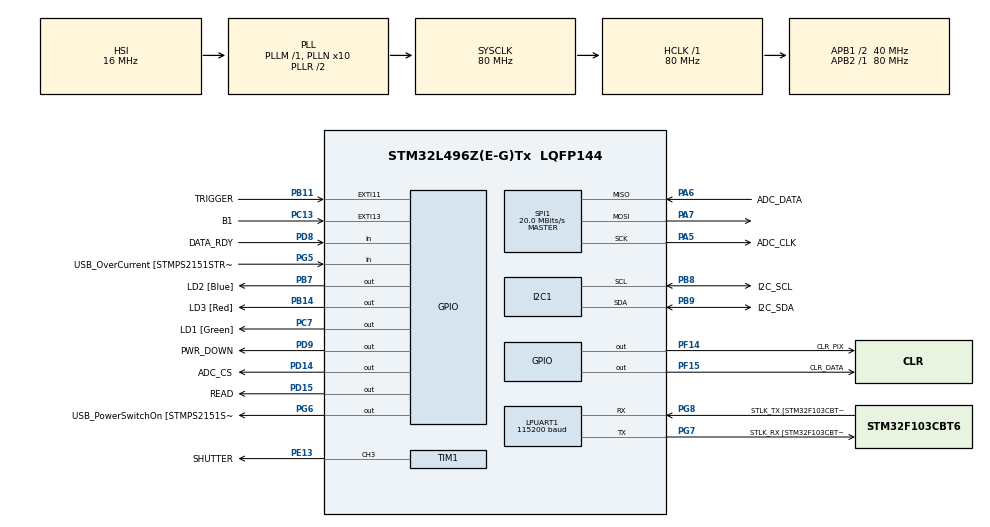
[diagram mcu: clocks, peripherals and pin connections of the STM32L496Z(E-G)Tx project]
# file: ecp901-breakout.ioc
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Dma.LPUART_RX.0.Direction=DMA_PERIPH_TO_MEMORY
Dma.LPUART_RX.0.Instance=DMA2_Channel7
Dma.LPUART_RX.0.MemDataAlignment=DMA_MDATAALIGN_BYTE
Dma.LPUART_RX.0.MemInc=DMA_MINC_ENABLE
Dma.LPUART_RX.0.Mode=DMA_CIRCULAR
Dma.LPUART_RX.0.PeriphDataAlignment=DMA_PDATAALIGN_BYTE
Dma.LPUART_RX.0.PeriphInc=DMA_PINC_DISABLE
Dma.LPUART_RX.0.Priority=DMA_PRIORITY_LOW
Dma.Request0=LPUART_RX
I2C1.Timing=0x00909BEB
LPUART1.BaudRate=115200
LPUART1.WordLength=UART_WORDLENGTH_8B
Mcu.Family=STM32L4
Mcu.Name=STM32L496Z(E-G)Tx
Mcu.Package=LQFP144
NVIC.DMA2_Channel7_IRQn=true\:0\:0\:false\:false\:true\:false\:true
NVIC.EXTI15_10_IRQn=true\:0\:0\:false\:false\:true\:true\:true
NVIC.PriorityGroup=NVIC_PRIORITYGROUP_4
PA10.GPIO_Label=USB_ID
PA10.Signal=USB_OTG_FS_ID
PA11.GPIO_Label=USB_DM
PA11.Signal=USB_OTG_FS_DM
PA12.GPIO_Label=USB_DP
PA12.Signal=USB_OTG_FS_DP
PA13\ (JTMS/SWDIO).GPIO_Label=TMS
PA13\ (JTMS/SWDIO).Mode=Trace_Asynchronous_SW
PA13\ (JTMS/SWDIO).Signal=SYS_JTMS-SWDIO
PA14\ (JTCK/SWCLK).GPIO_Label=TCK
PA14\ (JTCK/SWCLK).Mode=Trace_Asynchronous_SW
PA14\ (JTCK/SWCLK).Signal=SYS_JTCK-SWCLK
PA5.GPIO_Label=ADC_CLK
PA5.GPIO_PuPd=GPIO_NOPULL
PA5.GPIO_Speed=GPIO_SPEED_FREQ_MEDIUM
PA5.Mode=Full_Duplex_Master
PA5.Signal=SPI1_SCK
PA6.GPIO_Label=ADC_DATA
PA6.GPIO_PuPd=GPIO_NOPULL
PA6.GPIO_Speed=GPIO_SPEED_FREQ_LOW
PA6.Mode=Full_Duplex_Master
PA6.Signal=SPI1_MISO
PA7.GPIO_Speed=GPIO_SPEED_FREQ_LOW
PA7.Mode=Full_Duplex_Master
PA7.Signal=SPI1_MOSI
PA8.GPIO_Label=USB_SOF [TP1]
PA8.Signal=USB_OTG_FS_SOF
PA9.GPIO_Label=USB_VBUS
PA9.Signal=USB_OTG_FS_VBUS
PB11.GPIO_Label=TRIGGER
PB11.GPIO_ModeDefaultEXTI=GPIO_MODE_IT_RISING_FALLING
PB11.GPIO_PuPd=GPIO_PULLDOWN
PB11.Signal=GPXTI11
PB14.GPIO_Label=LD3 [Red]
PB14.Signal=GPIO_Output
PB3\ (JTDO/TRACESWO).GPIO_Label=SWO
PB3\ (JTDO/TRACESWO).Mode=Trace_Asynchronous_SW
PB3\ (JTDO/TRACESWO).Signal=SYS_JTDO-SWO
PB7.GPIO_Label=LD2 [Blue]
PB7.Signal=GPIO_Output
PB8.GPIO_Label=I2C_SCL
PB8.GPIO_Speed=GPIO_SPEED_FREQ_LOW
PB8.Mode=I2C
PB8.Signal=I2C1_SCL
PB9.GPIO_Label=I2C_SDA
PB9.GPIO_Speed=GPIO_SPEED_FREQ_LOW
PB9.Mode=I2C
PB9.Signal=I2C1_SDA
PC13.GPIO_Label=B1
PC13.Signal=GPXTI13
PC14-OSC32_IN\ (PC14).Mode=LSE-External-Oscillator
PC14-OSC32_IN\ (PC14).Signal=RCC_OSC32_IN
PC15-OSC32_OUT\ (PC15).Mode=LSE-External-Oscillator
PC15-OSC32_OUT\ (PC15).Signal=RCC_OSC32_OUT
PC7.GPIO_Label=LD1 [Green]
PC7.Signal=GPIO_Output
PD14.GPIO_Label=ADC_CS
PD14.Signal=GPIO_Output
PD15.GPIO_Label=READ
PD15.Signal=GPIO_Output
PD8.GPIO_Label=DATA_RDY
PD8.Signal=GPIO_Input
PD9.GPIO_Label=PWR_DOWN
PD9.GPIO_PuPd=GPIO_PULLUP
PD9.Signal=GPIO_Output
PE13.GPIO_Label=SHUTTER
PE13.Signal=S_TIM1_CH3
PF14.GPIO_Label=CLR_PIX
PF14.Signal=GPIO_Output
PF15.GPIO_Label=CLR_DATA
PF15.Signal=GPIO_Output
PG5.GPIO_Label=USB_OverCurrent [STMPS2151STR_FAULT]
PG5.Signal=GPIO_Input
PG6.GPIO_Label=USB_PowerSwitchOn [STMPS2151STR_EN]
PG6.Signal=GPIO_Output
PG7.GPIO_Label=STLK_RX [STM32F103CBT6_PA3]
PG7.Mode=Asynchronous
PG7.Signal=LPUART1_TX
PG8.GPIO_Label=STLK_TX [STM32F103CBT6_PA2]
PG8.Mode=Asynchronous
PG8.Signal=LPUART1_RX
PH1-OSC_OUT\ (PH1).Signal=RCC_OSC_OUT
ProjectManager.HeapSize=0x200
ProjectManager.StackSize=0x400
ProjectManager.TargetToolchain=STM32CubeIDE
RCC.48MHZClocksFreq_Value=24000000
RCC.ADCFreq_Value=192000000
RCC.AHBFreq_Value=80000000
RCC.APB1CLKDivider=RCC_HCLK_DIV2
RCC.APB1Freq_Value=40000000
RCC.APB1TimFreq_Value=80000000
RCC.APB2Freq_Value=80000000
RCC.APB2TimFreq_Value=80000000
RCC.CortexFreq_Value=80000000
RCC.HCLKFreq_Value=80000000
RCC.HSE_VALUE=8000000
RCC.HSI48_VALUE=48000000
RCC.HSI_VALUE=16000000
RCC.MSI_VALUE=4000000
RCC.PLLMUL=RCC_PLL_MUL9
RCC.PLLN=10
RCC.PLLSAI1N=24
RCC.PLLSourceVirtual=RCC_PLLSOURCE_HSI
RCC.PRESCALERUSB=RCC_USBCLKSOURCE_PLL_DIV1_5
RCC.SYSCLKFreq_VALUE=80000000
RCC.SYSCLKSource=RCC_SYSCLKSOURCE_PLLCLK
RCC.SYSCLKSourceVirtual=RCC_SYSCLKSOURCE_PLLCLK
RCC.USBFreq_Value=192000000
RCC.VCOOutputFreq_Value=160000000
SH.S_TIM1_CH3.0=TIM1_CH3,PWM Generation3 CH3
SPI1.BaudRatePrescaler=SPI_BAUDRATEPRESCALER_4
SPI1.CLKPhase=SPI_PHASE_2EDGE
SPI1.CLKPolarity=SPI_POLARITY_HIGH
SPI1.CalculateBaudRate=20.0 MBits/s
SPI1.DataSize=SPI_DATASIZE_8BIT
SPI1.Direction=SPI_DIRECTION_2LINES
SPI1.FirstBit=SPI_FIRSTBIT_MSB
SPI1.Mode=SPI_MODE_MASTER
SPI1.VirtualType=VM_MASTER
TIM1.Channel-PWM\ Generation3\ CH3=TIM_CHANNEL_3
TIM1.ClockDivision=TIM_CLOCKDIVISION_DIV1
TIM1.OCMode_PWM-PWM\ Generation3\ CH3=TIM_OCMODE_PWM2
VP_TIM1_VS_ClockSourceINT.Mode=Internal
VP_TIM1_VS_OPM.Mode=OPM_bit
board=NUCLEO-L496ZG

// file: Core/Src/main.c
/* USER CODE BEGIN Header */
/**
  ******************************************************************************
  * @file           : main.c
  * @brief          : Main program body
  ******************************************************************************
  * @attention
  *
  * <h2><center>&copy; Copyright (c) 2020 STMicroelectronics.
  * All rights reserved.</center></h2>
  *
  * This software component is licensed by ST under BSD 3-Clause license,
  * the "License"; You may not use this file except in compliance with the
  * License. You may obtain a copy of the License at:
  *                        opensource.org/licenses/BSD-3-Clause
  *
  ******************************************************************************
  */
/* USER CODE END Header */
#include "main.h"

/* USER CODE BEGIN Includes */
#include "App.hpp"
#include "dwt_stm32_delay.h"
/* USER CODE END Includes */

I2C_HandleTypeDef hi2c1;

UART_HandleTypeDef hlpuart1;
DMA_HandleTypeDef hdma_lpuart_rx;

SPI_HandleTypeDef hspi1;

TIM_HandleTypeDef htim1;

void SystemClock_Config(void);
static void MX_GPIO_Init(void);
static void MX_DMA_Init(void);
static void MX_LPUART1_UART_Init(void);
static void MX_I2C1_Init(void);
static void MX_SPI1_Init(void);
static void MX_TIM1_Init(void);

int main(void)
{

  /* MCU Configuration--------------------------------------------------------*/

  /* Reset of all peripherals, Initializes the Flash interface and the Systick. */
  HAL_Init();

  /* Configure the system clock */
  SystemClock_Config();

  /* Initialize all configured peripherals */
  MX_GPIO_Init();
  MX_DMA_Init();
  MX_LPUART1_UART_Init();
  MX_I2C1_Init();
  MX_SPI1_Init();
  MX_TIM1_Init();
  /* USER CODE BEGIN 2 */
  // init us delay function
  if (DWT_Delay_Init()) {
	  // failed to init delay
  }
  App_Setup(&hi2c1, &hlpuart1, &hspi1, &htim1);
  /* USER CODE END 2 */

  /* Infinite loop */
  /* USER CODE BEGIN WHILE */
  while (1)
  {
	  App_Loop();
    /* USER CODE END WHILE */

  }
}

void SystemClock_Config(void)
{
  RCC_OscInitTypeDef RCC_OscInitStruct = {0};
  RCC_ClkInitTypeDef RCC_ClkInitStruct = {0};
  RCC_PeriphCLKInitTypeDef PeriphClkInit = {0};

  /** Initializes the RCC Oscillators according to the specified parameters
  * in the RCC_OscInitTypeDef structure.
  */
  RCC_OscInitStruct.OscillatorType = RCC_OSCILLATORTYPE_HSI;
  RCC_OscInitStruct.HSIState = RCC_HSI_ON;
  RCC_OscInitStruct.HSICalibrationValue = RCC_HSICALIBRATION_DEFAULT;
  RCC_OscInitStruct.PLL.PLLState = RCC_PLL_ON;
  RCC_OscInitStruct.PLL.PLLSource = RCC_PLLSOURCE_HSI;
  RCC_OscInitStruct.PLL.PLLM = 1;
  RCC_OscInitStruct.PLL.PLLN = 10;
  RCC_OscInitStruct.PLL.PLLP = RCC_PLLP_DIV2;
  RCC_OscInitStruct.PLL.PLLQ = RCC_PLLQ_DIV2;
  RCC_OscInitStruct.PLL.PLLR = RCC_PLLR_DIV2;
  if (HAL_RCC_OscConfig(&RCC_OscInitStruct) != HAL_OK)
  {
    Error_Handler();
  }
  /** Initializes the CPU, AHB and APB buses clocks
  */
  RCC_ClkInitStruct.ClockType = RCC_CLOCKTYPE_HCLK|RCC_CLOCKTYPE_SYSCLK
                              |RCC_CLOCKTYPE_PCLK1|RCC_CLOCKTYPE_PCLK2;
  RCC_ClkInitStruct.SYSCLKSource = RCC_SYSCLKSOURCE_PLLCLK;
  RCC_ClkInitStruct.AHBCLKDivider = RCC_SYSCLK_DIV1;
  RCC_ClkInitStruct.APB1CLKDivider = RCC_HCLK_DIV2;
  RCC_ClkInitStruct.APB2CLKDivider = RCC_HCLK_DIV1;

  if (HAL_RCC_ClockConfig(&RCC_ClkInitStruct, FLASH_LATENCY_4) != HAL_OK)
  {
    Error_Handler();
  }
  PeriphClkInit.PeriphClockSelection = RCC_PERIPHCLK_LPUART1|RCC_PERIPHCLK_I2C1;
  PeriphClkInit.Lpuart1ClockSelection = RCC_LPUART1CLKSOURCE_PCLK1;
  PeriphClkInit.I2c1ClockSelection = RCC_I2C1CLKSOURCE_PCLK1;
  if (HAL_RCCEx_PeriphCLKConfig(&PeriphClkInit) != HAL_OK)
  {
    Error_Handler();
  }
  /** Configure the main internal regulator output voltage
  */
  if (HAL_PWREx_ControlVoltageScaling(PWR_REGULATOR_VOLTAGE_SCALE1) != HAL_OK)
  {
    Error_Handler();
  }
}

static void MX_I2C1_Init(void)
{

  hi2c1.Instance = I2C1;
  hi2c1.Init.Timing = 0x00909BEB;
  hi2c1.Init.OwnAddress1 = 0;
  hi2c1.Init.AddressingMode = I2C_ADDRESSINGMODE_7BIT;
  hi2c1.Init.DualAddressMode = I2C_DUALADDRESS_DISABLE;
  hi2c1.Init.OwnAddress2 = 0;
  hi2c1.Init.OwnAddress2Masks = I2C_OA2_NOMASK;
  hi2c1.Init.GeneralCallMode = I2C_GENERALCALL_DISABLE;
  hi2c1.Init.NoStretchMode = I2C_NOSTRETCH_DISABLE;
  if (HAL_I2C_Init(&hi2c1) != HAL_OK)
  {
    Error_Handler();
  }
  /** Configure Analogue filter
  */
  if (HAL_I2CEx_ConfigAnalogFilter(&hi2c1, I2C_ANALOGFILTER_ENABLE) != HAL_OK)
  {
    Error_Handler();
  }
  /** Configure Digital filter
  */
  if (HAL_I2CEx_ConfigDigitalFilter(&hi2c1, 0) != HAL_OK)
  {
    Error_Handler();
  }

}

static void MX_LPUART1_UART_Init(void)
{

  hlpuart1.Instance = LPUART1;
  hlpuart1.Init.BaudRate = 115200;
  hlpuart1.Init.WordLength = UART_WORDLENGTH_8B;
  hlpuart1.Init.StopBits = UART_STOPBITS_1;
  hlpuart1.Init.Parity = UART_PARITY_NONE;
  hlpuart1.Init.Mode = UART_MODE_TX_RX;
  hlpuart1.Init.HwFlowCtl = UART_HWCONTROL_NONE;
  hlpuart1.Init.OneBitSampling = UART_ONE_BIT_SAMPLE_DISABLE;
  hlpuart1.AdvancedInit.AdvFeatureInit = UART_ADVFEATURE_NO_INIT;
  if (HAL_UART_Init(&hlpuart1) != HAL_OK)
  {
    Error_Handler();
  }

}

static void MX_SPI1_Init(void)
{

  /* SPI1 parameter configuration*/
  hspi1.Instance = SPI1;
  hspi1.Init.Mode = SPI_MODE_MASTER;
  hspi1.Init.Direction = SPI_DIRECTION_2LINES;
  hspi1.Init.DataSize = SPI_DATASIZE_8BIT;
  hspi1.Init.CLKPolarity = SPI_POLARITY_HIGH;
  hspi1.Init.CLKPhase = SPI_PHASE_2EDGE;
  hspi1.Init.NSS = SPI_NSS_SOFT;
  hspi1.Init.BaudRatePrescaler = SPI_BAUDRATEPRESCALER_4;
  hspi1.Init.FirstBit = SPI_FIRSTBIT_MSB;
  hspi1.Init.TIMode = SPI_TIMODE_DISABLE;
  hspi1.Init.CRCCalculation = SPI_CRCCALCULATION_DISABLE;
  hspi1.Init.CRCPolynomial = 7;
  hspi1.Init.CRCLength = SPI_CRC_LENGTH_DATASIZE;
  hspi1.Init.NSSPMode = SPI_NSS_PULSE_DISABLE;
  if (HAL_SPI_Init(&hspi1) != HAL_OK)
  {
    Error_Handler();
  }

}

static void MX_TIM1_Init(void)
{

  TIM_ClockConfigTypeDef sClockSourceConfig = {0};
  TIM_MasterConfigTypeDef sMasterConfig = {0};
  TIM_OC_InitTypeDef sConfigOC = {0};
  TIM_BreakDeadTimeConfigTypeDef sBreakDeadTimeConfig = {0};

  htim1.Instance = TIM1;
  htim1.Init.Prescaler = 0;
  htim1.Init.CounterMode = TIM_COUNTERMODE_UP;
  htim1.Init.Period = 65535;
  htim1.Init.ClockDivision = TIM_CLOCKDIVISION_DIV1;
  htim1.Init.RepetitionCounter = 0;
  htim1.Init.AutoReloadPreload = TIM_AUTORELOAD_PRELOAD_DISABLE;
  if (HAL_TIM_Base_Init(&htim1) != HAL_OK)
  {
    Error_Handler();
  }
  sClockSourceConfig.ClockSource = TIM_CLOCKSOURCE_INTERNAL;
  if (HAL_TIM_ConfigClockSource(&htim1, &sClockSourceConfig) != HAL_OK)
  {
    Error_Handler();
  }
  if (HAL_TIM_PWM_Init(&htim1) != HAL_OK)
  {
    Error_Handler();
  }
  if (HAL_TIM_OnePulse_Init(&htim1, TIM_OPMODE_SINGLE) != HAL_OK)
  {
    Error_Handler();
  }
  sMasterConfig.MasterOutputTrigger = TIM_TRGO_RESET;
  sMasterConfig.MasterOutputTrigger2 = TIM_TRGO2_RESET;
  sMasterConfig.MasterSlaveMode = TIM_MASTERSLAVEMODE_DISABLE;
  if (HAL_TIMEx_MasterConfigSynchronization(&htim1, &sMasterConfig) != HAL_OK)
  {
    Error_Handler();
  }
  sConfigOC.OCMode = TIM_OCMODE_PWM2;
  sConfigOC.Pulse = 0;
  sConfigOC.OCPolarity = TIM_OCPOLARITY_HIGH;
  sConfigOC.OCNPolarity = TIM_OCNPOLARITY_HIGH;
  sConfigOC.OCFastMode = TIM_OCFAST_DISABLE;
  sConfigOC.OCIdleState = TIM_OCIDLESTATE_RESET;
  sConfigOC.OCNIdleState = TIM_OCNIDLESTATE_RESET;
  if (HAL_TIM_PWM_ConfigChannel(&htim1, &sConfigOC, TIM_CHANNEL_3) != HAL_OK)
  {
    Error_Handler();
  }
  sBreakDeadTimeConfig.OffStateRunMode = TIM_OSSR_DISABLE;
  sBreakDeadTimeConfig.OffStateIDLEMode = TIM_OSSI_DISABLE;
  sBreakDeadTimeConfig.LockLevel = TIM_LOCKLEVEL_OFF;
  sBreakDeadTimeConfig.DeadTime = 0;
  sBreakDeadTimeConfig.BreakState = TIM_BREAK_DISABLE;
  sBreakDeadTimeConfig.BreakPolarity = TIM_BREAKPOLARITY_HIGH;
  sBreakDeadTimeConfig.BreakFilter = 0;
  sBreakDeadTimeConfig.Break2State = TIM_BREAK2_DISABLE;
  sBreakDeadTimeConfig.Break2Polarity = TIM_BREAK2POLARITY_HIGH;
  sBreakDeadTimeConfig.Break2Filter = 0;
  sBreakDeadTimeConfig.AutomaticOutput = TIM_AUTOMATICOUTPUT_DISABLE;
  if (HAL_TIMEx_ConfigBreakDeadTime(&htim1, &sBreakDeadTimeConfig) != HAL_OK)
  {
    Error_Handler();
  }
  HAL_TIM_MspPostInit(&htim1);

}

static void MX_DMA_Init(void)
{

  /* DMA controller clock enable */
  __HAL_RCC_DMA2_CLK_ENABLE();

  /* DMA interrupt init */
  /* DMA2_Channel7_IRQn interrupt configuration */
  HAL_NVIC_SetPriority(DMA2_Channel7_IRQn, 0, 0);
  HAL_NVIC_EnableIRQ(DMA2_Channel7_IRQn);

}

static void MX_GPIO_Init(void)
{
  GPIO_InitTypeDef GPIO_InitStruct = {0};

  /* GPIO Ports Clock Enable */
  __HAL_RCC_GPIOC_CLK_ENABLE();
  __HAL_RCC_GPIOH_CLK_ENABLE();
  __HAL_RCC_GPIOA_CLK_ENABLE();
  __HAL_RCC_GPIOF_CLK_ENABLE();
  __HAL_RCC_GPIOE_CLK_ENABLE();
  __HAL_RCC_GPIOB_CLK_ENABLE();
  __HAL_RCC_GPIOD_CLK_ENABLE();
  __HAL_RCC_GPIOG_CLK_ENABLE();
  HAL_PWREx_EnableVddIO2();

  /*Configure GPIO pin Output Level */
  HAL_GPIO_WritePin(GPIOF, CLR_PIX_Pin|CLR_DATA_Pin, GPIO_PIN_RESET);

  /*Configure GPIO pin Output Level */
  HAL_GPIO_WritePin(GPIOB, LD3_Pin|LD2_Pin, GPIO_PIN_RESET);

  /*Configure GPIO pin Output Level */
  HAL_GPIO_WritePin(GPIOD, PWR_DOWN_Pin|ADC_CS_Pin|READ_Pin, GPIO_PIN_RESET);

  /*Configure GPIO pin Output Level */
  HAL_GPIO_WritePin(USB_PowerSwitchOn_GPIO_Port, USB_PowerSwitchOn_Pin, GPIO_PIN_RESET);

  /*Configure GPIO pin Output Level */
  HAL_GPIO_WritePin(LD1_GPIO_Port, LD1_Pin, GPIO_PIN_RESET);

  /*Configure GPIO pin : B1_Pin */
  GPIO_InitStruct.Pin = B1_Pin;
  GPIO_InitStruct.Mode = GPIO_MODE_IT_RISING;
  GPIO_InitStruct.Pull = GPIO_NOPULL;
  HAL_GPIO_Init(B1_GPIO_Port, &GPIO_InitStruct);

  /*Configure GPIO pins : CLR_PIX_Pin CLR_DATA_Pin */
  GPIO_InitStruct.Pin = CLR_PIX_Pin|CLR_DATA_Pin;
  GPIO_InitStruct.Mode = GPIO_MODE_OUTPUT_PP;
  GPIO_InitStruct.Pull = GPIO_NOPULL;
  GPIO_InitStruct.Speed = GPIO_SPEED_FREQ_LOW;
  HAL_GPIO_Init(GPIOF, &GPIO_InitStruct);

  /*Configure GPIO pin : TRIGGER_Pin */
  GPIO_InitStruct.Pin = TRIGGER_Pin;
  GPIO_InitStruct.Mode = GPIO_MODE_IT_RISING_FALLING;
  GPIO_InitStruct.Pull = GPIO_PULLDOWN;
  HAL_GPIO_Init(TRIGGER_GPIO_Port, &GPIO_InitStruct);

  /*Configure GPIO pins : LD3_Pin LD2_Pin */
  GPIO_InitStruct.Pin = LD3_Pin|LD2_Pin;
  GPIO_InitStruct.Mode = GPIO_MODE_OUTPUT_PP;
  GPIO_InitStruct.Pull = GPIO_NOPULL;
  GPIO_InitStruct.Speed = GPIO_SPEED_FREQ_LOW;
  HAL_GPIO_Init(GPIOB, &GPIO_InitStruct);

  /*Configure GPIO pin : DATA_RDY_Pin */
  GPIO_InitStruct.Pin = DATA_RDY_Pin;
  GPIO_InitStruct.Mode = GPIO_MODE_INPUT;
  GPIO_InitStruct.Pull = GPIO_NOPULL;
  HAL_GPIO_Init(DATA_RDY_GPIO_Port, &GPIO_InitStruct);

  /*Configure GPIO pin : PWR_DOWN_Pin */
  GPIO_InitStruct.Pin = PWR_DOWN_Pin;
  GPIO_InitStruct.Mode = GPIO_MODE_OUTPUT_PP;
  GPIO_InitStruct.Pull = GPIO_PULLUP;
  GPIO_InitStruct.Speed = GPIO_SPEED_FREQ_LOW;
  HAL_GPIO_Init(PWR_DOWN_GPIO_Port, &GPIO_InitStruct);

  /*Configure GPIO pins : ADC_CS_Pin READ_Pin */
  GPIO_InitStruct.Pin = ADC_CS_Pin|READ_Pin;
  GPIO_InitStruct.Mode = GPIO_MODE_OUTPUT_PP;
  GPIO_InitStruct.Pull = GPIO_NOPULL;
  GPIO_InitStruct.Speed = GPIO_SPEED_FREQ_LOW;
  HAL_GPIO_Init(GPIOD, &GPIO_InitStruct);

  /*Configure GPIO pin : USB_OverCurrent_Pin */
  GPIO_InitStruct.Pin = USB_OverCurrent_Pin;
  GPIO_InitStruct.Mode = GPIO_MODE_INPUT;
  GPIO_InitStruct.Pull = GPIO_NOPULL;
  HAL_GPIO_Init(USB_OverCurrent_GPIO_Port, &GPIO_InitStruct);

  /*Configure GPIO pin : USB_PowerSwitchOn_Pin */
  GPIO_InitStruct.Pin = USB_PowerSwitchOn_Pin;
  GPIO_InitStruct.Mode = GPIO_MODE_OUTPUT_PP;
  GPIO_InitStruct.Pull = GPIO_NOPULL;
  GPIO_InitStruct.Speed = GPIO_SPEED_FREQ_LOW;
  HAL_GPIO_Init(USB_PowerSwitchOn_GPIO_Port, &GPIO_InitStruct);

  /*Configure GPIO pin : LD1_Pin */
  GPIO_InitStruct.Pin = LD1_Pin;
  GPIO_InitStruct.Mode = GPIO_MODE_OUTPUT_PP;
  GPIO_InitStruct.Pull = GPIO_NOPULL;
  GPIO_InitStruct.Speed = GPIO_SPEED_FREQ_LOW;
  HAL_GPIO_Init(LD1_GPIO_Port, &GPIO_InitStruct);

  /*Configure GPIO pins : USB_SOF_Pin USB_ID_Pin USB_DM_Pin USB_DP_Pin */
  GPIO_InitStruct.Pin = USB_SOF_Pin|USB_ID_Pin|USB_DM_Pin|USB_DP_Pin;
  GPIO_InitStruct.Mode = GPIO_MODE_AF_PP;
  GPIO_InitStruct.Pull = GPIO_NOPULL;
  GPIO_InitStruct.Speed = GPIO_SPEED_FREQ_VERY_HIGH;
  GPIO_InitStruct.Alternate = GPIO_AF10_OTG_FS;
  HAL_GPIO_Init(GPIOA, &GPIO_InitStruct);

  /* EXTI interrupt init*/
  HAL_NVIC_SetPriority(EXTI15_10_IRQn, 0, 0);
  HAL_NVIC_EnableIRQ(EXTI15_10_IRQn);

}

void Error_Handler(void)
{
}

/************************ (C) COPYRIGHT STMicroelectronics *****END OF FILE****/
